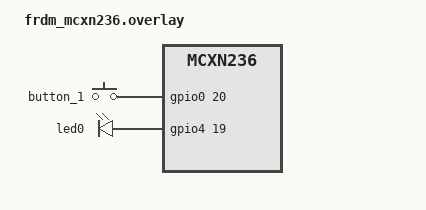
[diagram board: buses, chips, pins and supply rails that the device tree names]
/ {
    aliases {
        my-button = &button_1;
        my-led = &led0;
    };

    buttons {
        compatible = "gpio-keys";
        debounce-interval-ms = <50>;
        polling-mode;

        button_1: d0_20 {
            gpios = <&gpio0 20 (GPIO_ACTIVE_HIGH | GPIO_PULL_DOWN)>;
        };
    };

    leds {
        compatible = "gpio-leds";
        led0: d4_19 {
            gpios = <&gpio4 19 GPIO_ACTIVE_HIGH>;
        };
    };
};
